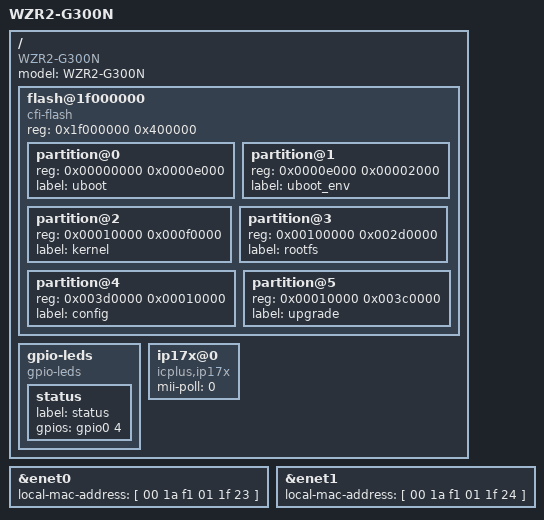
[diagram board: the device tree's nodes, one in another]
/*
 * Copyright (c) 2015 Hiroki Mori
 *
 * Redistribution and use in source and binary forms, with or without
 * modification, are permitted provided that the following conditions
 * are met:
 * 1. Redistributions of source code must retain the above copyright
 *    notice, this list of conditions and the following disclaimer.
 * 2. Redistributions in binary form must reproduce the above copyright
 *    notice, this list of conditions and the following disclaimer in the
 *    documentation and/or other materials provided with the distribution.
 *
 * THIS SOFTWARE IS PROVIDED BY THE AUTHOR AND CONTRIBUTORS ``AS IS'' AND
 * ANY EXPRESS OR IMPLIED WARRANTIES, INCLUDING, BUT NOT LIMITED TO, THE
 * IMPLIED WARRANTIES OF MERCHANTABILITY AND FITNESS FOR A PARTICULAR PURPOSE
 * ARE DISCLAIMED. IN NO EVENT SHALL THE AUTHOR OR CONTRIBUTORS BE LIABLE
 * FOR ANY DIRECT, INDIRECT, INCIDENTAL, SPECIAL, EXEMPLARY, OR CONSEQUENTIAL
 * DAMAGES (INCLUDING, BUT NOT LIMITED TO, PROCUREMENT OF SUBSTITUTE GOODS
 * OR SERVICES; LOSS OF USE, DATA, OR PROFITS; OR BUSINESS INTERRUPTION)
 * HOWEVER CAUSED AND ON ANY THEORY OF LIABILITY, WHETHER IN CONTRACT, STRICT
 * LIABILITY, OR TORT (INCLUDING NEGLIGENCE OR OTHERWISE) ARISING IN ANY WAY
 * OUT OF THE USE OF THIS SOFTWARE, EVEN IF ADVISED OF THE POSSIBILITY OF
 * SUCH DAMAGE.
 *
 * Buffalo WZR2-G300N Device Tree Source.
 *
 * $FreeBSD$
 */

/dts-v1/;

#include "rt1310a.dtsi"

/ {
	compatible = "WZR2-G300N", "ralink,rt1310a-soc";
	model = "WZR2-G300N";

	flash@1f000000 {
		#address-cells = <1>;
		#size-cells = <1>;
		compatible = "cfi-flash";
		reg = <0x1f000000 0x400000>;		// 4M at 0x1f000000

		partition@0 {
			reg = <0x00000000 0x0000e000>;
			label = "uboot";
		};
		partition@1 {
			reg = <0x0000e000 0x00002000>;
			label = "uboot_env";
		};
		partition@2 {
			reg = <0x00010000 0x000f0000>;
			label = "kernel";
		};
		partition@3 {
			reg = <0x00100000 0x002d0000>;
			label = "rootfs";
		};
		partition@4 {
			reg = <0x003d0000 0x00010000>;
			label = "config";
		};
		partition@5 {
			reg = <0x00010000 0x003c0000>;
			label = "upgrade";
		};
	};

	gpio-leds {
		compatible = "gpio-leds";

		status {
			label = "status";
			gpios = <&gpio0 4 0>;
		};
	};

	ip17x@0 {
		compatible = "icplus,ip17x";
		mii-poll = <0>;
	};

};

&enet0 {
	local-mac-address = [ 00 1a f1 01 1f 23 ];
};

&enet1 {
	local-mac-address = [ 00 1a f1 01 1f 24 ];
};
